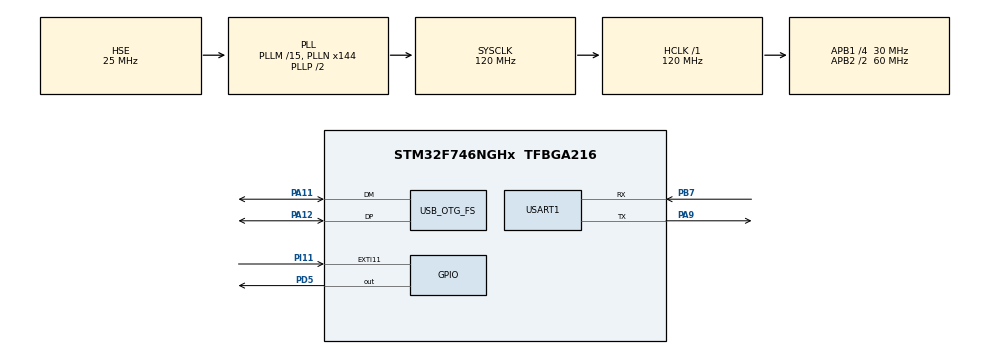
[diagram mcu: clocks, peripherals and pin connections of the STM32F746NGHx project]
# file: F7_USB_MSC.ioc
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Mcu.Family=STM32F7
Mcu.Name=STM32F746NGHx
Mcu.Package=TFBGA216
NVIC.EXTI15_10_IRQn=true\:0\:0\:false\:false\:true\:true\:true
NVIC.OTG_FS_IRQn=true\:0\:0\:false\:false\:true\:false\:true
NVIC.PriorityGroup=NVIC_PRIORITYGROUP_4
PA11.Mode=Host_Only
PA11.Signal=USB_OTG_FS_DM
PA12.Mode=Host_Only
PA12.Signal=USB_OTG_FS_DP
PA9.Mode=Asynchronous
PA9.Signal=USART1_TX
PB7.Mode=Asynchronous
PB7.Signal=USART1_RX
PC14/OSC32_IN.Mode=LSE-External-Oscillator
PC14/OSC32_IN.Signal=RCC_OSC32_IN
PC15/OSC32_OUT.Mode=LSE-External-Oscillator
PC15/OSC32_OUT.Signal=RCC_OSC32_OUT
PD5.Signal=GPIO_Output
PH0/OSC_IN.Mode=HSE-External-Oscillator
PH0/OSC_IN.Signal=RCC_OSC_IN
PH1/OSC_OUT.Mode=HSE-External-Oscillator
PH1/OSC_OUT.Signal=RCC_OSC_OUT
PI11.GPIO_PuPd=GPIO_PULLDOWN
PI11.Signal=GPXTI11
ProjectManager.HeapSize=0x2000
ProjectManager.StackSize=0x2000
ProjectManager.TargetToolchain=STM32CubeIDE
RCC.AHBFreq_Value=120000000
RCC.APB1CLKDivider=RCC_HCLK_DIV4
RCC.APB1Freq_Value=30000000
RCC.APB1TimFreq_Value=60000000
RCC.APB2CLKDivider=RCC_HCLK_DIV2
RCC.APB2Freq_Value=60000000
RCC.APB2TimFreq_Value=120000000
RCC.CortexFreq_Value=120000000
RCC.HCLKFreq_Value=120000000
RCC.HSE_VALUE=25000000
RCC.HSI_VALUE=16000000
RCC.PLLI2SN=100
RCC.PLLM=15
RCC.PLLN=144
RCC.PLLQ=5
RCC.PLLSAIN=92
RCC.PLLSAIP=RCC_PLLSAIP_DIV4
RCC.PLLSAIR=5
RCC.PLLSAIRDiv=RCC_PLLSAIDIVR_8
RCC.SDMMCClockSelection=RCC_SDMMC1CLKSOURCE_CLK48
RCC.SYSCLKFreq_VALUE=120000000
RCC.SYSCLKSource=RCC_SYSCLKSOURCE_PLLCLK
RCC.USBFreq_Value=48000000
RCC.VCOOutputFreq_Value=240000000
USART1.VirtualMode-Asynchronous=VM_ASYNC
USB_HOST.BSP.number=1
USB_HOST.USBH_HandleTypeDef-ALL_Classes_FS=hUsbHostFS
USB_HOST.VirtualModeFS=All_Classes
USB_HOST0.BSP.STBoard=false
USB_HOST0.BSP.api=Unknown
USB_HOST0.BSP.i2caddr=0
USB_HOST0.BSP.instance=PD5
USB_HOST0.BSP.ip=GPIO
USB_HOST0.BSP.mode=Output
USB_HOST0.BSP.name=Drive_VBUS_FS
USB_HOST0.BSP.solution=PD5
USB_OTG_FS.VirtualMode=Host_Only
USB_OTG_FS.phy_itface=HCD_PHY_EMBEDDED
VP_FATFS_VS_USB.Mode=USB
VP_USB_HOST_VS_USB_HOST_ALL_CLASS_FS.Mode=ALL_Classes_FS
board=STM32F746G-DISCO

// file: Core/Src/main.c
/* USER CODE BEGIN Header */
/**
  ******************************************************************************
  * @file           : main.c
  * @brief          : Main program body
  ******************************************************************************
  * @attention
  *
  * <h2><center>&copy; Copyright (c) 2020 STMicroelectronics.
  * All rights reserved.</center></h2>
  *
  * This software component is licensed by ST under Ultimate Liberty license
  * SLA0044, the "License"; You may not use this file except in compliance with
  * the License. You may obtain a copy of the License at:
  *                             www.st.com/SLA0044
  *
  ******************************************************************************
  */
/* USER CODE END Header */

#include "main.h"
#include "fatfs.h"
#include "usb_host.h"

/* USER CODE BEGIN Includes */
#include <stdio.h>
/* USER CODE END Includes */

/* USER CODE BEGIN PD */
#define PUTCHAR_PROTOTYPE int __io_putchar(int ch)
/* USER CODE END PD */

UART_HandleTypeDef huart1;

/* USER CODE BEGIN PV */
volatile uint8_t state = 0;
/* USER CODE END PV */

void SystemClock_Config(void);
static void MX_GPIO_Init(void);
static void MX_USART1_UART_Init(void);
void MX_USB_HOST_Process(void);

int main(void)
{

  /* MCU Configuration--------------------------------------------------------*/

  /* Reset of all peripherals, Initializes the Flash interface and the Systick. */
  HAL_Init();

  /* Configure the system clock */
  SystemClock_Config();

  /* Initialize all configured peripherals */
  MX_GPIO_Init();
  MX_USART1_UART_Init();
  MX_FATFS_Init();
  MX_USB_HOST_Init();
  /* USER CODE BEGIN 2 */
  printf("Press the blue button\n\n");
  /* USER CODE END 2 */

  /* Infinite loop */
  while (1)
  {
    MX_USB_HOST_Process();

    if(state)
    {
    	state = 0;
    	printf("Test Function\n");
    	UserFunction();
    }
  }
}

void SystemClock_Config(void)
{
  RCC_OscInitTypeDef RCC_OscInitStruct = {0};
  RCC_ClkInitTypeDef RCC_ClkInitStruct = {0};
  RCC_PeriphCLKInitTypeDef PeriphClkInitStruct = {0};

  /** Configure LSE Drive Capability
  */
  HAL_PWR_EnableBkUpAccess();
  /** Configure the main internal regulator output voltage
  */
  __HAL_RCC_PWR_CLK_ENABLE();
  __HAL_PWR_VOLTAGESCALING_CONFIG(PWR_REGULATOR_VOLTAGE_SCALE3);
  /** Initializes the CPU, AHB and APB busses clocks
  */
  RCC_OscInitStruct.OscillatorType = RCC_OSCILLATORTYPE_HSE;
  RCC_OscInitStruct.HSEState = RCC_HSE_ON;
  RCC_OscInitStruct.PLL.PLLState = RCC_PLL_ON;
  RCC_OscInitStruct.PLL.PLLSource = RCC_PLLSOURCE_HSE;
  RCC_OscInitStruct.PLL.PLLM = 15;
  RCC_OscInitStruct.PLL.PLLN = 144;
  RCC_OscInitStruct.PLL.PLLP = RCC_PLLP_DIV2;
  RCC_OscInitStruct.PLL.PLLQ = 5;
  if (HAL_RCC_OscConfig(&RCC_OscInitStruct) != HAL_OK)
  {
    Error_Handler();
  }
  /** Initializes the CPU, AHB and APB busses clocks
  */
  RCC_ClkInitStruct.ClockType = RCC_CLOCKTYPE_HCLK|RCC_CLOCKTYPE_SYSCLK
                              |RCC_CLOCKTYPE_PCLK1|RCC_CLOCKTYPE_PCLK2;
  RCC_ClkInitStruct.SYSCLKSource = RCC_SYSCLKSOURCE_PLLCLK;
  RCC_ClkInitStruct.AHBCLKDivider = RCC_SYSCLK_DIV1;
  RCC_ClkInitStruct.APB1CLKDivider = RCC_HCLK_DIV4;
  RCC_ClkInitStruct.APB2CLKDivider = RCC_HCLK_DIV2;

  if (HAL_RCC_ClockConfig(&RCC_ClkInitStruct, FLASH_LATENCY_3) != HAL_OK)
  {
    Error_Handler();
  }
  PeriphClkInitStruct.PeriphClockSelection = RCC_PERIPHCLK_USART1|RCC_PERIPHCLK_CLK48;
  PeriphClkInitStruct.Usart1ClockSelection = RCC_USART1CLKSOURCE_PCLK2;
  PeriphClkInitStruct.Clk48ClockSelection = RCC_CLK48SOURCE_PLL;
  if (HAL_RCCEx_PeriphCLKConfig(&PeriphClkInitStruct) != HAL_OK)
  {
    Error_Handler();
  }
}

static void MX_USART1_UART_Init(void)
{

  huart1.Instance = USART1;
  huart1.Init.BaudRate = 115200;
  huart1.Init.WordLength = UART_WORDLENGTH_8B;
  huart1.Init.StopBits = UART_STOPBITS_1;
  huart1.Init.Parity = UART_PARITY_NONE;
  huart1.Init.Mode = UART_MODE_TX_RX;
  huart1.Init.HwFlowCtl = UART_HWCONTROL_NONE;
  huart1.Init.OverSampling = UART_OVERSAMPLING_16;
  huart1.Init.OneBitSampling = UART_ONE_BIT_SAMPLE_DISABLE;
  huart1.AdvancedInit.AdvFeatureInit = UART_ADVFEATURE_NO_INIT;
  if (HAL_UART_Init(&huart1) != HAL_OK)
  {
    Error_Handler();
  }

}

static void MX_GPIO_Init(void)
{
  GPIO_InitTypeDef GPIO_InitStruct = {0};

  /* GPIO Ports Clock Enable */
  __HAL_RCC_GPIOB_CLK_ENABLE();
  __HAL_RCC_GPIOA_CLK_ENABLE();
  __HAL_RCC_GPIOD_CLK_ENABLE();
  __HAL_RCC_GPIOC_CLK_ENABLE();
  __HAL_RCC_GPIOI_CLK_ENABLE();
  __HAL_RCC_GPIOH_CLK_ENABLE();

  /*Configure GPIO pin Output Level */
  HAL_GPIO_WritePin(GPIOD, GPIO_PIN_5, GPIO_PIN_RESET);

  /*Configure GPIO pin : PD5 */
  GPIO_InitStruct.Pin = GPIO_PIN_5;
  GPIO_InitStruct.Mode = GPIO_MODE_OUTPUT_PP;
  GPIO_InitStruct.Pull = GPIO_NOPULL;
  GPIO_InitStruct.Speed = GPIO_SPEED_FREQ_LOW;
  HAL_GPIO_Init(GPIOD, &GPIO_InitStruct);

  /*Configure GPIO pin : PI11 */
  GPIO_InitStruct.Pin = GPIO_PIN_11;
  GPIO_InitStruct.Mode = GPIO_MODE_IT_RISING;
  GPIO_InitStruct.Pull = GPIO_PULLDOWN;
  HAL_GPIO_Init(GPIOI, &GPIO_InitStruct);

  /* EXTI interrupt init*/
  HAL_NVIC_SetPriority(EXTI15_10_IRQn, 0, 0);
  HAL_NVIC_EnableIRQ(EXTI15_10_IRQn);

}

/* USER CODE BEGIN 4 */
int _write(int file,char *ptr, int len)
{
	HAL_UART_Transmit(&huart1, (uint8_t *)ptr, len, 10);
	return len;
}

void HAL_GPIO_EXTI_Callback(uint16_t GPIO_Pin)
{

	if(GPIO_Pin == GPIO_PIN_11)
	{
		state = 1;
	}
}
/* USER CODE END 4 */

void Error_Handler(void)
{
}

/************************ (C) COPYRIGHT STMicroelectronics *****END OF FILE****/
